# efuse_mmr: IP-XACT component
VLNV tenstorrent.com:ocah:efuse_mmr:1.0

## Address spaces and blocks
efuse_mmr_mmap.efuse_mmr: base 'h0, range 'h74, width 32

## Registers
Registers are 32-bit, read-only, reset 0x0 unless marked. A register's access mark holds for its fields unless they carry their own. Offsets are from the block's base; lines under a group give offsets from that group; [hi:lo] are bit positions; {n}, {i} and the like mark numbered series; 'fields as' and 'values as' point back to an identical list; <NAME> marks a mode.

## efuse_mmr_mmap.efuse_mmr — Security-token input and match-status registers for RMA and secure-disable eFuse tokens.
Base 0x00000000
{0x0+4i} RMA_SIP_TOKEN_I[{i}] (i=0..7) rw reset not defined — Software-writeable RMA token word. The assembled token is hashed and compared against the fused value to authorize lifecycle (LC) state transitions.
  [31:0] token — Portion of writeable version of RMA_*_TOKEN, hashed, and compared with fused value to allow LC to change states.
{0x20+4i} RMA_CHIPLET_TOKEN_I[{i}] (i=0..7) rw reset not defined — Software-writeable RMA token word. The assembled token is hashed and compared against the fused value to authorize lifecycle (LC) state transitions.
  fields as RMA_SIP_TOKEN_I[0]
{0x40+4i} SEC_DISABLE_TOKEN_I[{i}] (i=0..7) rw reset not defined — Software-writeable security-disable token word. The assembled token is hashed and compared against the post-silicon injected value to authorize security_disable.
  [31:0] token — Portion of writeable version of SEC_DISABLE_TOKEN, hashed, and compared with the post silicon injected values to allow security_disable.
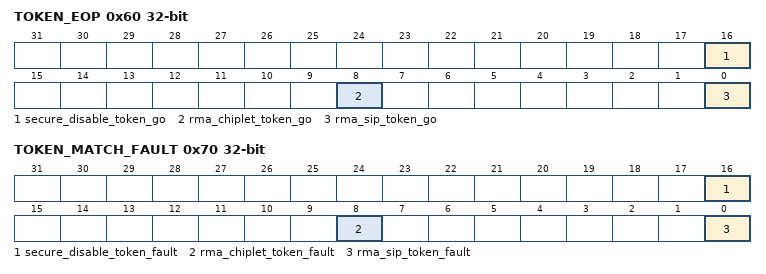
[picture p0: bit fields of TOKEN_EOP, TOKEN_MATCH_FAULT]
0x60 TOKEN_EOP wo — Token end-of-packet control. Writing the per-token go bit signals that all token words have been written and triggers a pulse to begin token hashing.
  [16] secure_disable_token_go — Write 1 to indicate that all token data has been written; this generates a pulse to begin token hashing.
  [8] rma_chiplet_token_go — Write 1 to indicate that all token data has been written; this generates a pulse to begin token hashing.
  [0] rma_sip_token_go — Write 1 to indicate that all token data has been written; this generates a pulse to begin token hashing.
0x64 RMA_SIP_TOKEN_MATCH — Token match status. Reports the result of the token hash comparison (match, mismatch, or error).
  [5:0] token_match_status — Store the status of the token match. Match = 6'b010101, Mismatch = 6'b101010, Error = 6'b111111
0x68 RMA_CHIPLET_TOKEN_MATCH — Token match status. Reports the result of the token hash comparison (match, mismatch, or error).
  fields as RMA_SIP_TOKEN_MATCH
0x6C SEC_DISABLE_TOKEN_MATCH — Token match status. Reports the result of the token hash comparison (match, mismatch, or error).
  fields as RMA_SIP_TOKEN_MATCH
0x70 TOKEN_MATCH_FAULT — Token comparator redundancy fault status. The token match logic is triple redundant and is not a majority vote: all three comparators must agree and each must drive a legal differential pair. A bit sets when the comparators for that token disagree, which may indicate a fault injection or FIB attack. The corresponding token_match_status then reads the error code 6'b111111 and an interrupt is raised to the SEP CPU. Bits are sticky until reset.
  [16] secure_disable_token_fault — A redundancy fault was detected in the SEC_DISABLE_TOKEN comparators.
  [8] rma_chiplet_token_fault — A redundancy fault was detected in the RMA_CHIPLET_TOKEN comparators.
  [0] rma_sip_token_fault — A redundancy fault was detected in the RMA_SIP_TOKEN comparators.

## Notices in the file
SPDX-License-Identifier: Apache-2.0
SPDX-FileCopyrightText: 2026 Tenstorrent USA, Inc.
